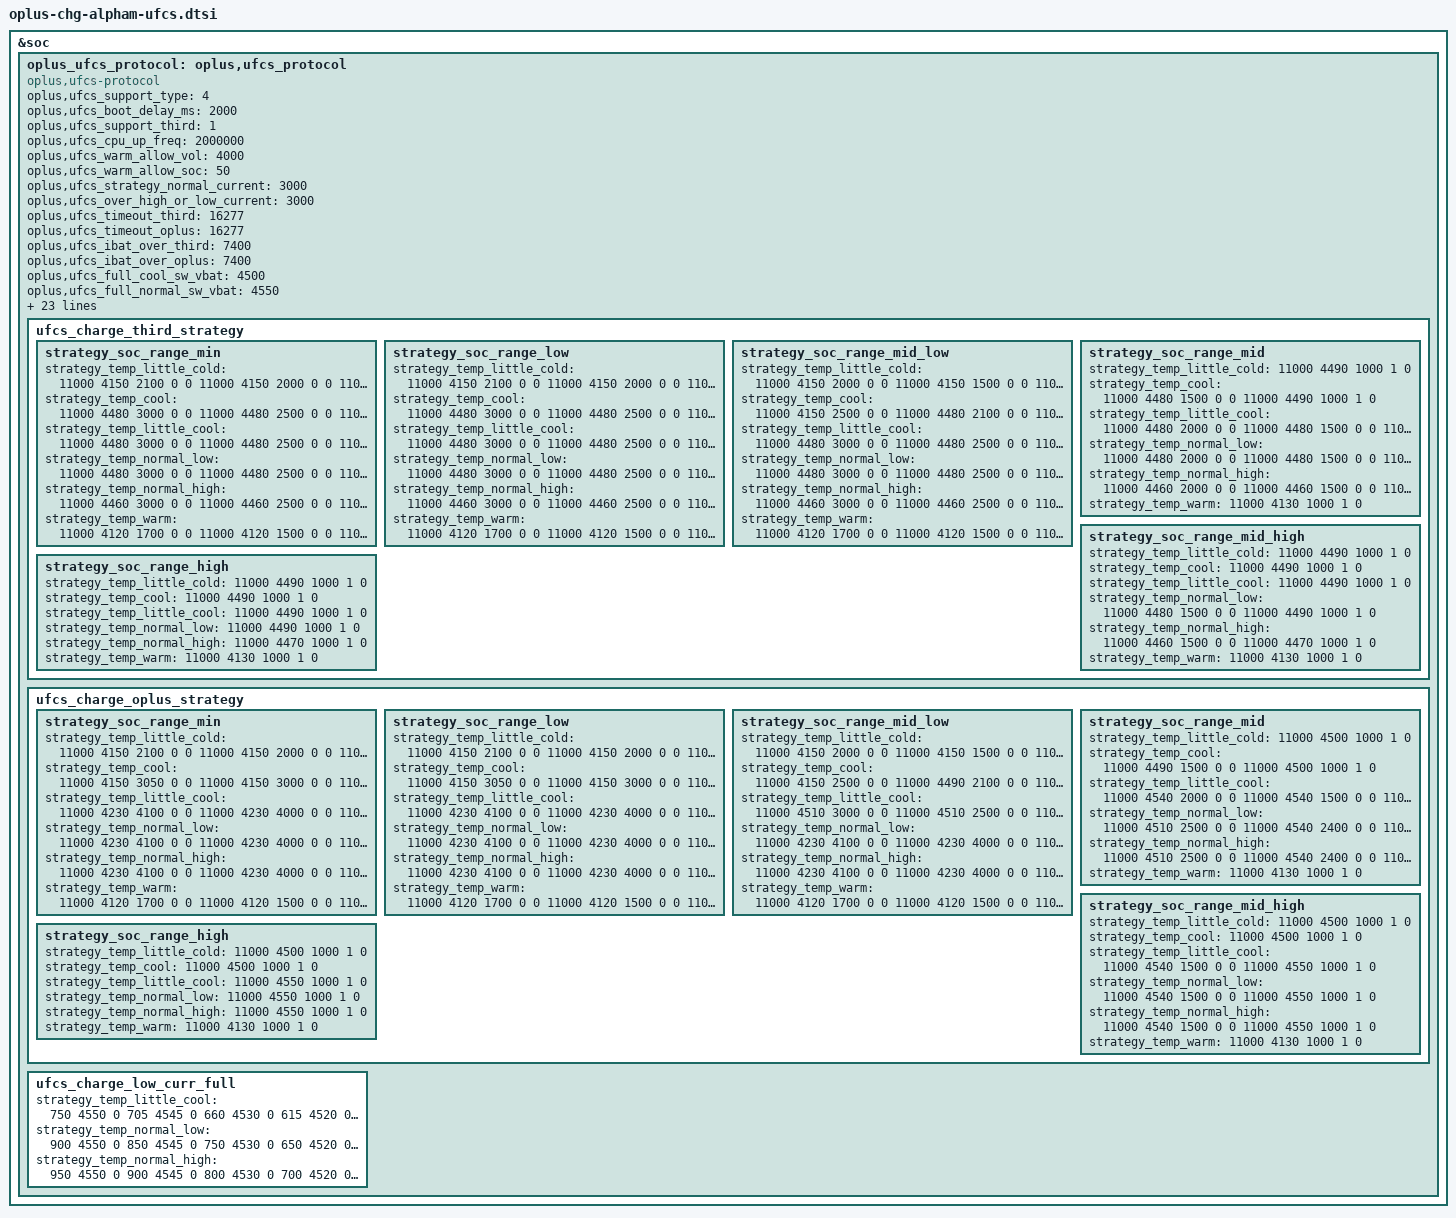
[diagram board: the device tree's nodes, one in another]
&soc {
	oplus_ufcs_protocol: oplus,ufcs_protocol {
		status = "ok";
		compatible = "oplus,ufcs-protocol";
	};
};

&oplus_ufcs_protocol {
	oplus,ufcs_support_type = <4>;
	oplus,ufcs_boot_delay_ms = <2000>;
	oplus,ufcs_support_third = <1>;
	oplus,ufcs_cpu_up_freq = <2000000>;
	oplus,ufcs_warm_allow_vol = <4000>;
	oplus,ufcs_warm_allow_soc = <50>;
	oplus,ufcs_strategy_normal_current = <3000>;//6A
	oplus,ufcs_over_high_or_low_current = <3000>;
	oplus,ufcs_timeout_third = <16277>;
	oplus,ufcs_timeout_oplus = <16277>;
	oplus,ufcs_ibat_over_third = <7400>;
	oplus,ufcs_ibat_over_oplus = <7400>;
	oplus,ufcs_full_cool_sw_vbat = <4500>;
	oplus,ufcs_full_normal_sw_vbat = <4550>;
	oplus,ufcs_full_normal_hw_vbat = <4560>;
	oplus,ufcs_full_ffc_vbat = <4485>;
	oplus,ufcs_full_warm_vbat = <4130>;
	oplus,ufcs_full_cool_sw_vbat_third = <4490>;
	oplus,ufcs_full_normal_sw_vbat_third= <4490>;
	oplus,ufcs_full_normal_hw_vbat_third = <4500>;
	oplus,ufcs_freq_mincore = <2208000>;
	oplus,ufcs_freq_midcore = <2208000>;
	oplus,ufcs_freq_maxcore = <2208000>;
	oplus,ufcs_current_change_timeout = <100>;
	oplus,ufcs_r_default = <270 45 10 45 20 20 20>;
	oplus,ufcs_rmos_mohm = <5>;
	oplus,ufcs_r_limit = <150 80 70 50 30>;
	oplus,ufcs_strategy_batt_high_temp = <400 420 430 390 410 420>;
	oplus,ufcs_strategy_high_current = <3000 2000 2000 3000 3000 3000>;
	oplus,ufcs_charge_strategy_soc = <0 20 35 50 75 85 95>;
	oplus,ufcs_charge_strategy_temp = <0 50 120 200 350 440 530>;
	oplus,ufcs_low_curr_full_strategy_temp = <120 200 350 440>;

	ufcs_charge_third_strategy {
		strategy_soc_range_min {
			strategy_temp_little_cold =	<11000 4150 2100 0 0
							 11000 4150 2000 0 0
							 11000 4150 1500 0 0
							 11000 4480 1450 0 0
							 11000 4490 1000 1 0>;
			strategy_temp_cool =		<11000 4480 3000 0 0
							 11000 4480 2500 0 0
							 11000 4480 2400 0 0
							 11000 4480 2000 0 0
							 11000 4480 1500 0 0
							 11000 4490 1000 1 0>;
			strategy_temp_little_cool =	<11000 4480 3000 0 0
							 11000 4480 2500 0 0
							 11000 4480 2400 0 0
							 11000 4480 2000 0 0
							 11000 4480 1500 0 0
							 11000 4490 1000 1 0>;
			strategy_temp_normal_low =	<11000 4480 3000 0 0
							 11000 4480 2500 0 0
							 11000 4480 2400 0 0
							 11000 4480 2000 0 0
							 11000 4480 1500 0 0
							 11000 4490 1000 1 0>;
			strategy_temp_normal_high =	<11000 4460 3000 0 0
							 11000 4460 2500 0 0
							 11000 4460 2400 0 0
							 11000 4460 2000 0 0
							 11000 4460 1500 0 0
							 11000 4470 1000 1 0>;
			strategy_temp_warm =		<11000 4120 1700 0 0
							 11000 4120 1500 0 0
							 11000 4130 1000 1 0>;
		};
		strategy_soc_range_low {
			strategy_temp_little_cold =	<11000 4150 2100 0 0
							 11000 4150 2000 0 0
							 11000 4150 1500 0 0
							 11000 4480 1450 0 0
							 11000 4490 1000 1 0>;
			strategy_temp_cool =		<11000 4480 3000 0 0
							 11000 4480 2500 0 0
							 11000 4480 2400 0 0
							 11000 4480 2000 0 0
							 11000 4480 1500 0 0
							 11000 4490 1000 1 0>;
			strategy_temp_little_cool =	<11000 4480 3000 0 0
							 11000 4480 2500 0 0
							 11000 4480 2400 0 0
							 11000 4480 2000 0 0
							 11000 4480 1500 0 0
							 11000 4490 1000 1 0>;
			strategy_temp_normal_low =	<11000 4480 3000 0 0
							 11000 4480 2500 0 0
							 11000 4480 2400 0 0
							 11000 4480 2000 0 0
							 11000 4480 1500 0 0
							 11000 4490 1000 1 0>;
			strategy_temp_normal_high =	<11000 4460 3000 0 0
							 11000 4460 2500 0 0
							 11000 4460 2400 0 0
							 11000 4460 2000 0 0
							 11000 4460 1500 0 0
							 11000 4470 1000 1 0>;
			strategy_temp_warm =		<11000 4120 1700 0 0
							 11000 4120 1500 0 0
							 11000 4130 1000 1 0>;
		};
		strategy_soc_range_mid_low {
			strategy_temp_little_cold =	<11000 4150 2000 0 0
							 11000 4150 1500 0 0
							 11000 4480 1450 0 0
							 11000 4490 1000 1 0>;
			strategy_temp_cool =		<11000 4150 2500 0 0
							 11000 4480 2100 0 0
							 11000 4480 2000 0 0
							 11000 4480 1500 0 0
							 11000 4490 1000 1 0>;
			strategy_temp_little_cool =	<11000 4480 3000 0 0
							 11000 4480 2500 0 0
							 11000 4480 2400 0 0
							 11000 4480 2000 0 0
							 11000 4480 1500 0 0
							 11000 4490 1000 1 0>;
			strategy_temp_normal_low =	<11000 4480 3000 0 0
							 11000 4480 2500 0 0
							 11000 4480 2400 0 0
							 11000 4480 2000 0 0
							 11000 4480 1500 0 0
							 11000 4490 1000 1 0>;
			strategy_temp_normal_high =	<11000 4460 3000 0 0
							 11000 4460 2500 0 0
							 11000 4460 2400 0 0
							 11000 4460 2000 0 0
							 11000 4460 1500 0 0
							 11000 4470 1000 1 0>;
			strategy_temp_warm =		<11000 4120 1700 0 0
							 11000 4120 1500 0 0
							 11000 4130 1000 1 0>;
		};
		strategy_soc_range_mid {
			strategy_temp_little_cold =	<11000 4490 1000 1 0>;
			strategy_temp_cool =		<11000 4480 1500 0 0
							 11000 4490 1000 1 0>;
			strategy_temp_little_cool =	<11000 4480 2000 0 0
							 11000 4480 1500 0 0
							 11000 4490 1000 1 0>;
			strategy_temp_normal_low =	<11000 4480 2000 0 0
							 11000 4480 1500 0 0
							 11000 4490 1000 1 0>;
			strategy_temp_normal_high =	<11000 4460 2000 0 0
							 11000 4460 1500 0 0
							 11000 4470 1000 1 0>;
		strategy_temp_warm =		<11000 4130 1000 1 0>;
		};
		strategy_soc_range_mid_high {
			strategy_temp_little_cold =	<11000 4490 1000 1 0>;
			strategy_temp_cool =		<11000 4490 1000 1 0>;
			strategy_temp_little_cool =	<11000 4490 1000 1 0>;
			strategy_temp_normal_low =	<11000 4480 1500 0 0
						 11000 4490 1000 1 0>;
			strategy_temp_normal_high =	<11000 4460 1500 0 0
						 11000 4470 1000 1 0>;
			strategy_temp_warm =		<11000 4130 1000 1 0>;
		};
		strategy_soc_range_high {
			strategy_temp_little_cold =	<11000 4490 1000 1 0>;
			strategy_temp_cool =		<11000 4490 1000 1 0>;
			strategy_temp_little_cool =	<11000 4490 1000 1 0>;
			strategy_temp_normal_low =	<11000 4490 1000 1 0>;
			strategy_temp_normal_high =	<11000 4470 1000 1 0>;
			strategy_temp_warm =		<11000 4130 1000 1 0>;
		};
};
ufcs_charge_oplus_strategy {
		strategy_soc_range_min {
			strategy_temp_little_cold =	<11000 4150 2100 0 0
							 11000 4150 2000 0 0
							 11000 4150 1500 0 0
							 11000 4490 1450 0 0
							 11000 4500 1000 1 0>;
			strategy_temp_cool =		<11000 4150 3050 0 0
							 11000 4150 3000 0 0
							 11000 4150 2500 0 0
							 11000 4490 2100 0 0
							 11000 4490 2000 0 0
							 11000 4490 1500 0 0
							 11000 4500 1000 1 0>;
			strategy_temp_little_cool =	<11000 4230 4100 0 0
							 11000 4230 4000 0 0
							 11000 4510 3650 0 0
							 11000 4510 3500 0 0
							 11000 4510 3000 0 0
							 11000 4510 2500 0 0
							 11000 4540 2400 0 0
							 11000 4540 2000 0 0
							 11000 4540 1500 0 0
							 11000 4550 1000 1 0>;
			strategy_temp_normal_low =	<11000 4230 4100 0 0
							 11000 4230 4000 0 0
							 11000 4510 3650 0 0
							 11000 4510 3500 0 0
							 11000 4510 3000 0 0
							 11000 4510 2500 0 0
							 11000 4540 2400 0 0
							 11000 4540 2000 0 0
							 11000 4540 1500 0 0
							 11000 4550 1000 1 0>;
			strategy_temp_normal_high =	<11000 4230 4100 0 0
							 11000 4230 4000 0 0
							 11000 4510 3650 0 0
							 11000 4510 3500 0 0
							 11000 4510 3000 0 0
							 11000 4510 2500 0 0
							 11000 4540 2400 0 0
							 11000 4540 2000 0 0
							 11000 4540 1500 0 0
							 11000 4550 1000 1 0>;
			strategy_temp_warm =		<11000 4120 1700 0 0
							 11000 4120 1500 0 0
							 11000 4130 1000 1 0>;
		};
		strategy_soc_range_low {
			strategy_temp_little_cold =	<11000 4150 2100 0 0
							 11000 4150 2000 0 0
							 11000 4150 1500 0 0
							 11000 4490 1450 0 0
							 11000 4500 1000 1 0>;
			strategy_temp_cool =		<11000 4150 3050 0 0
							 11000 4150 3000 0 0
							 11000 4150 2500 0 0
							 11000 4490 2100 0 0
							 11000 4490 2000 0 0
							 11000 4490 1500 0 0
							 11000 4500 1000 1 0>;
			strategy_temp_little_cool =	<11000 4230 4100 0 0
							 11000 4230 4000 0 0
							 11000 4510 3650 0 0
							 11000 4510 3500 0 0
							 11000 4510 3000 0 0
							 11000 4510 2500 0 0
							 11000 4540 2400 0 0
							 11000 4540 2000 0 0
							 11000 4540 1500 0 0
							 11000 4550 1000 1 0>;
			strategy_temp_normal_low =	<11000 4230 4100 0 0
							 11000 4230 4000 0 0
							 11000 4510 3650 0 0
							 11000 4510 3500 0 0
							 11000 4510 3000 0 0
							 11000 4510 2500 0 0
							 11000 4540 2400 0 0
							 11000 4540 2000 0 0
							 11000 4540 1500 0 0
							 11000 4550 1000 1 0>;
			strategy_temp_normal_high =	<11000 4230 4100 0 0
							 11000 4230 4000 0 0
							 11000 4510 3650 0 0
							 11000 4510 3500 0 0
							 11000 4510 3000 0 0
							 11000 4510 2500 0 0
							 11000 4540 2400 0 0
							 11000 4540 2000 0 0
							 11000 4540 1500 0 0
							 11000 4550 1000 1 0>;
			strategy_temp_warm =		<11000 4120 1700 0 0
							 11000 4120 1500 0 0
							 11000 4130 1000 1 0>;
		};
		strategy_soc_range_mid_low {
			strategy_temp_little_cold =	<11000 4150 2000 0 0
							 11000 4150 1500 0 0
							 11000 4490 1450 0 0
							 11000 4500 1000 1 0>;
			strategy_temp_cool =		<11000 4150 2500 0 0
							 11000 4490 2100 0 0
							 11000 4490 2000 0 0
							 11000 4490 1500 0 0
							 11000 4500 1000 1 0>;
			strategy_temp_little_cool =	<11000 4510 3000 0 0
							 11000 4510 2500 0 0
							 11000 4540 2400 0 0
							 11000 4540 2000 0 0
							 11000 4540 1500 0 0
							 11000 4550 1000 1 0>;
			strategy_temp_normal_low =	<11000 4230 4100 0 0
							 11000 4230 4000 0 0
							 11000 4510 3650 0 0
							 11000 4510 3500 0 0
							 11000 4510 3000 0 0
							 11000 4510 2500 0 0
							 11000 4540 2400 0 0
							 11000 4540 2000 0 0
							 11000 4540 1500 0 0
							 11000 4550 1000 1 0>;
			strategy_temp_normal_high =	<11000 4230 4100 0 0
							 11000 4230 4000 0 0
							 11000 4510 3650 0 0
							 11000 4510 3500 0 0
							 11000 4510 3000 0 0
							 11000 4510 2500 0 0
							 11000 4540 2400 0 0
							 11000 4540 2000 0 0
							 11000 4540 1500 0 0
							 11000 4550 1000 1 0>;
			strategy_temp_warm =		<11000 4120 1700 0 0
							 11000 4120 1500 0 0
							 11000 4130 1000 1 0>;
		};
		strategy_soc_range_mid {
			strategy_temp_little_cold =	<11000 4500 1000 1 0>;
			strategy_temp_cool =		<11000 4490 1500 0 0
							 11000 4500 1000 1 0>;
			strategy_temp_little_cool =	<11000 4540 2000 0 0
							 11000 4540 1500 0 0
							 11000 4550 1000 0 0>;
			strategy_temp_normal_low =	<11000 4510 2500 0 0
							 11000 4540 2400 0 0
							 11000 4540 2000 0 0
							 11000 4540 1500 0 0
							 11000 4550 1000 1 0>;
			strategy_temp_normal_high =	<11000 4510 2500 0 0
							 11000 4540 2400 0 0
							 11000 4540 2000 0 0
							 11000 4540 1500 0 0
							 11000 4550 1000 1 0>;
		strategy_temp_warm =		<11000 4130 1000 1 0>;
	};
	strategy_soc_range_mid_high {
		strategy_temp_little_cold =	<11000 4500 1000 1 0>;
		strategy_temp_cool =		<11000 4500 1000 1 0>;
		strategy_temp_little_cool =	<11000 4540 1500 0 0
						 11000 4550 1000 1 0>;
		strategy_temp_normal_low =	<11000 4540 1500 0 0
						 11000 4550 1000 1 0>;
		strategy_temp_normal_high =	<11000 4540 1500 0 0
						 11000 4550 1000 1 0>;
		strategy_temp_warm =		<11000 4130 1000 1 0>;
	};
	strategy_soc_range_high {
		strategy_temp_little_cold =	<11000 4500 1000 1 0>;
		strategy_temp_cool =		<11000 4500 1000 1 0>;
		strategy_temp_little_cool =	<11000 4550 1000 1 0>;
		strategy_temp_normal_low =	<11000 4550 1000 1 0>;
		strategy_temp_normal_high =	<11000 4550 1000 1 0>;
		strategy_temp_warm =		<11000 4130 1000 1 0>;
	};
};
ufcs_charge_low_curr_full {
	strategy_temp_little_cool = 	<750 4550 0
					 705 4545 0
					 660 4530 0
					 615 4520 0
					 570 4510 1>;
	strategy_temp_normal_low =	<900 4550 0
					 850 4545 0
					 750 4530 0
					 650 4520 0
					 500 4510 1>;
	strategy_temp_normal_high = 	<950 4550 0
					 900 4545 0
					 800 4530 0
					 700 4520 0
					 550 4510 1>;
};
};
